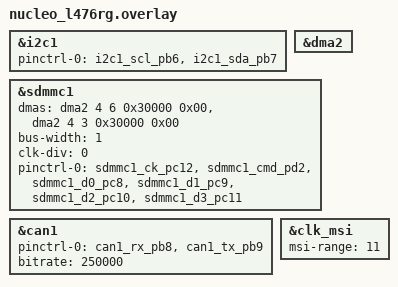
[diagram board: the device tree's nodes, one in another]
#include <freq.h>

&i2c1 {
	pinctrl-0 = <&i2c1_scl_pb6 &i2c1_sda_pb7>;
};

/*
&spi1 {
	pinctrl-0 = <&spi1_sck_pa5 &spi1_miso_pa6 &spi1_mosi_pa7>;
	cs-gpios = <&gpioa 4 (GPIO_ACTIVE_LOW | GPIO_PULL_UP)>;

	sdmmc: sdmmc@0 {
		compatible = "zephyr,sdhc-spi-slot";
		reg = <0>;
		status = "okay";
		spi-max-frequency = <DT_FREQ_M(25)>;

		mmc {
			compatible = "zephyr,sdmmc-disk";
			status = "okay";
		};
	};
};
*/

&dma2 {
	status = "okay";
};

/delete-node/ &spi3;
&sdmmc1 {
	dmas = <&dma2 4 6 0x30000 0x00>, <&dma2 4 3 0x30000 0x00>;
	dma-names = "tx", "rx";
	bus-width = <1>;
	clk-div = <0>;
	pinctrl-0 = <
		&sdmmc1_ck_pc12
		&sdmmc1_cmd_pd2
		&sdmmc1_d0_pc8
		&sdmmc1_d1_pc9
		&sdmmc1_d2_pc10
		&sdmmc1_d3_pc11
	>;
	pinctrl-names = "default";
	status = "okay";
};

&can1 {
	pinctrl-0 = <&can1_rx_pb8 &can1_tx_pb9>;
	pinctrl-names = "default";
	bitrate = <250000>;
	status = "okay";
};

&clk_msi {
	msi-range = <11>; /* ~48 MHz */
	status = "okay";
};

/*
&clk_hse {
	hse-bypass;
	clock-frequency = <DT_FREQ_M(8)>;
	status = "okay";
};

&pll {
	div-m = <1>;
	mul-n = <20>;
	div-r = <2>;
	clocks = <&clk_hse>;
	status = "okay";
};

&rcc {
	clocks = <&pll>;
	clock-frequency = <DT_FREQ_M(80)>;
	ahb-prescaler = <1>;
	apb1-prescaler = <1>;
	apb2-prescaler = <1>;
};
*/
